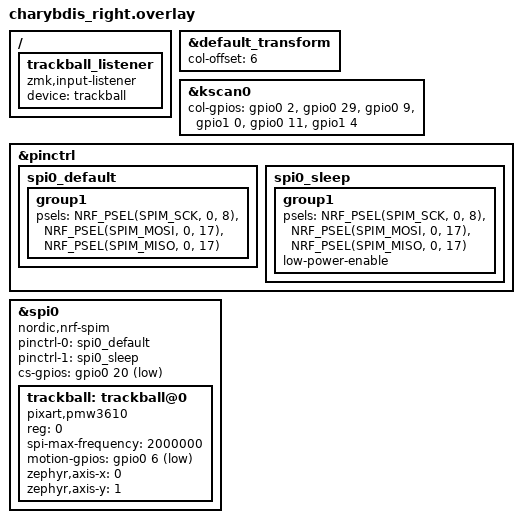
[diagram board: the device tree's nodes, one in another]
/*
 * Copyright (c) 2020 ZMK Contributors
 *
 * SPDX-License-Identifier: MIT
 */
 
#include "charybdis.dtsi"

&default_transform {
    col-offset = <6>;
}; 

&kscan0 {
	col-gpios
		= <&gpio0 2 (GPIO_ACTIVE_HIGH | GPIO_PULL_DOWN)>
		, <&gpio0 29 (GPIO_ACTIVE_HIGH | GPIO_PULL_DOWN)>
		, <&gpio0 9 (GPIO_ACTIVE_HIGH | GPIO_PULL_DOWN)>
		, <&gpio1 0  (GPIO_ACTIVE_HIGH | GPIO_PULL_DOWN)>
		, <&gpio0 11 (GPIO_ACTIVE_HIGH | GPIO_PULL_DOWN)>
		, <&gpio1 4  (GPIO_ACTIVE_HIGH | GPIO_PULL_DOWN)>
		;
};

// trackball bus
&pinctrl {
    spi0_default: spi0_default {
        group1 {
            psels = <NRF_PSEL(SPIM_SCK, 0, 8)>,
                <NRF_PSEL(SPIM_MOSI, 0, 17)>,
                <NRF_PSEL(SPIM_MISO, 0, 17)>;
        };
    };

    spi0_sleep: spi0_sleep {
        group1 {
            psels = <NRF_PSEL(SPIM_SCK, 0, 8)>,
                <NRF_PSEL(SPIM_MOSI, 0, 17)>,
                <NRF_PSEL(SPIM_MISO, 0, 17)>;
            low-power-enable;
        };
    };
};

&spi0 {
    status = "okay";
    compatible = "nordic,nrf-spim";
    pinctrl-0 = <&spi0_default>;
    pinctrl-1 = <&spi0_sleep>;
    pinctrl-names = "default", "sleep";
    cs-gpios = <&gpio0 20 GPIO_ACTIVE_LOW>;

    trackball: trackball@0 {
        status = "okay";
        compatible = "pixart,pmw3610";
        reg = <0>;
        spi-max-frequency = <2000000>;
        // The new Zephyr driver requires motion-gpios instead of irq-gpios.
        motion-gpios = <&gpio0 6 (GPIO_ACTIVE_LOW | GPIO_PULL_UP)>;
        // Zephyr driver requires explicitly assigning axis codes.
        // INPUT_REL_X = 0, INPUT_REL_Y = 1
        zephyr,axis-x = <0>; 
        zephyr,axis-y = <1>; 
        // Note: The new driver does not natively know about scroll-layers. 
        // We leave them here to see if ZMK's pointing driver handles it, but 
        // if not, we might need a separate ZMK input processor.
        // scroll-layers = <1>;
    };
};


//RGB bus

/ {
    trackball_listener {
        compatible = "zmk,input-listener";
        device = <&trackball>;
    };
};
